# MCU_CPSW0_NUSS register map
Vendor: Texas Instruments
Peripheral module from a debugger description file (folder am65x).
Registers are 32-bit, read-write, reset 0x0 unless marked. A register's access mark holds for its fields unless they carry their own. Offsets are as the file gives them; lines under a group give offsets from that group; [hi:lo] are bit positions; {n}, {i} and the like mark numbered series; 'fields as' and 'values as' point back to an identical list; <NAME> marks a mode.

## MCU_CPSW0_NUSS (part 1 of 2)
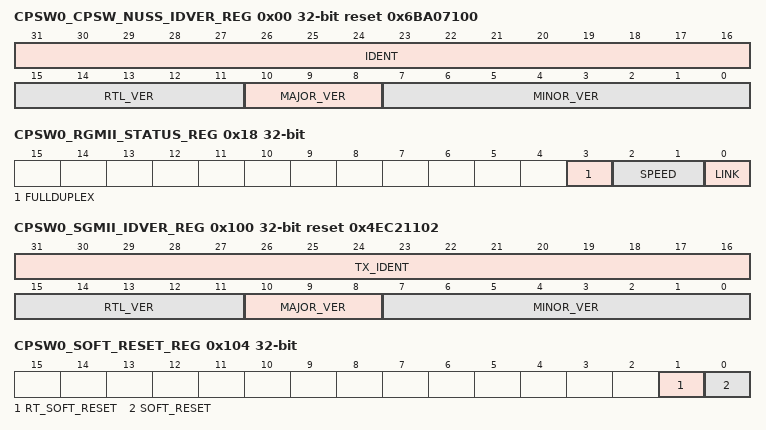
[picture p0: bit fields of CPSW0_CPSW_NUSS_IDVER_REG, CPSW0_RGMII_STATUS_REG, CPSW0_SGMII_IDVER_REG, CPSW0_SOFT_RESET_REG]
0x00 CPSW0_CPSW_NUSS_IDVER_REG ro reset 0x6BA07100 — ID Version Register
  [31:16] IDENT — Identification value
  [15:11] RTL_VER — RTL version value
  [10:8] MAJOR_VER — Major version value
  [7:0] MINOR_VER — Minor version value
0x04 CPSW0_SYNCE_COUNT_REG — SyncE Count Register
  [31:0] SYNCE_CNT — Sync E Count Value
0x08 CPSW0_SYNCE_MUX_REG — SyncE Mux Register
  [5:0] SYNCE_SEL — Sync E Select Value
0x10 CPSW0_SGMII_MODE_REG reset 0x1 — SyncE Mux Register
  [0] SYNCE_SEL — SGMII_MODE Input
0x18 CPSW0_RGMII_STATUS_REG ro — RGMII Status Register
  [3] FULLDUPLEX — Rgmii full dulex: 0=Half-duplex, 1=Full-duplex
  [2:1] SPEED — Rgmii speed: 00=10Mbps, 01=100Mbps, 10=1000Mbps, 11=reserved
  [0] LINK — Rgmii link indicator: 0=Link is down, 1=Link is up
0x1C CPSW0_SUBSSYSTEM_STATUS_REG ro — Subsystem Status Register
  [0] EEE_CLKSTOP_ACK — Energy Efficient Ethernet clockstop acknowledge from MCU_CPSW0_NUSS
0x100 CPSW0_SGMII_IDVER_REG ro reset 0x4EC21102 — SGMII Identification and Version Register.
  [31:16] TX_IDENT
  [15:11] RTL_VER — RTL version value
  [10:8] MAJOR_VER — Major version value
  [7:0] MINOR_VER — Minor version value
0x104 CPSW0_SOFT_RESET_REG — Software Reset Register.
  [1] RT_SOFT_RESET — Transmit and receive software reset
  [0] SOFT_RESET — Software reset
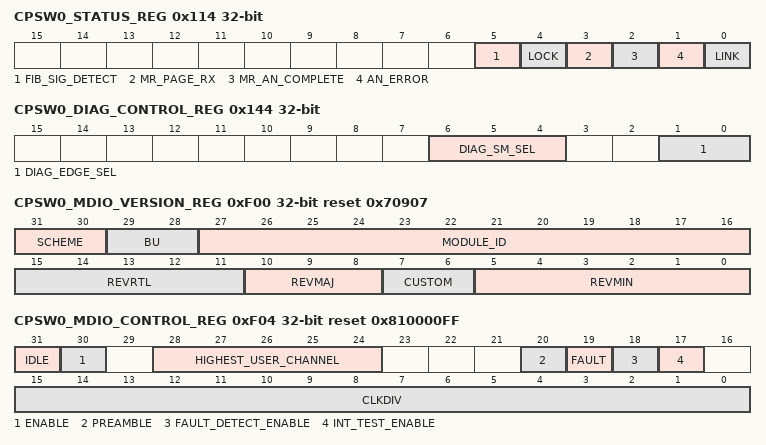
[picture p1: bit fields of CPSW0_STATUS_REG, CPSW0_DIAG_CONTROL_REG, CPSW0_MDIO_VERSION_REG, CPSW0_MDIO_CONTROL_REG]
0x114 CPSW0_STATUS_REG ro — Status Register.
  [5] FIB_SIG_DETECT — Fiber signal detect
  [4] LOCK
  [3] MR_PAGE_RX — Next page received
  [2] MR_AN_COMPLETE — Auto-negotiation complete
  [1] AN_ERROR — Auto-negotiation error
  [0] LINK — Link indicator
0x118 CPSW0_MR_ADV_ABILITY_REG — Advertised Ability Register.
  [15:0] MR_ADV_ABILITY — Advertised ability
0x11C CPSW0_MR_NP_TX_REG — Transmit Next Page Register.
  [15:0] MR_NP_TX — Next page transmit
0x120 CPSW0_MR_LP_ADV_ABILITY_REG ro — Link Partner Advertised Ability.
  [15:0] MR_LP_ADV_ABILITY — Link partner advertised ability
0x124 CPSW0_MR_LP_NP_RX_REG ro — Link Partner Receive Next Page Register.
  [15:0] MR_LP_NP_RX — Link Partner Next Page Received
0x130 CPSW0_TX_CFG_REG
  [31:0] TX_CFG — Transmit configuration register output
0x134 CPSW0_RX_CFG_REG
  [31:0] RX_CFG — Receive configuration register output
0x138 CPSW0_AUX_CFG_REG
  [31:0] AUX_CFG — Auxiliary configuration register output
0x140 CPSW0_DIAG_CLEAR_REG
  [0] DIAG_CLEAR — Diagnostics clear
0x144 CPSW0_DIAG_CONTROL_REG
  [6:4] DIAG_SM_SEL — Diagnostic select
  [1:0] DIAG_EDGE_SEL — Diagnostics hold signals edge select
0x148 CPSW0_DIAG_STATUS_REG ro
  [15:0] DIAG_STATUS — Diagnostics status
0xF00 CPSW0_MDIO_VERSION_REG ro reset 0x70907 — version_reg
  [31:30] SCHEME
  [29:28] BU
  [27:16] MODULE_ID
  [15:11] REVRTL — RTL version
  [10:8] REVMAJ — Major version
  [7:6] CUSTOM — Custom version
  [5:0] REVMIN — Minor version
0xF04 CPSW0_MDIO_CONTROL_REG access per field reset 0x810000FF
  [31] IDLE ro — MDIO state machine idle
  [30] ENABLE rw
  [28:24] HIGHEST_USER_CHANNEL ro
  [20] PREAMBLE rw — Preamble disable
  [19] FAULT rw — Fault indicator
  [18] FAULT_DETECT_ENABLE rw
  [17] INT_TEST_ENABLE rw — Interrupt test enable
  [15:0] CLKDIV rw — Clock divider
0xF08 CPSW0_ALIVE_REG — MDIO PHY Acknowledge Status Register
  [31:0] ALIVE — MDIO alive
0xF0C CPSW0_LINK_REG ro
  [31:0] LINK — MDIO link state
0xF10 CPSW0_LINK_INT_RAW_REG
  [1:0] LINKINTRAW — MDIO link change event raw value
0xF14 CPSW0_LINK_INT_MASKED_REG
  [1:0] LINKINTMASKED — MDIO link change interrupt masked value
0xF18 CPSW0_LINK_INT_MASK_SET_REG
  [0] LINKINTMASKSET — MDIO link interrupt mask set
0xF1C CPSW0_LINK_INT_MASK_CLEAR_REG
  [0] LINKINTMASKCLR — MDIO link interrupt mask clear
0xF20 CPSW0_USER_INT_RAW_REG
  [1:0] USERINTRAW — User interrupt raw
0xF24 CPSW0_USER_INT_MASKED_REG
  [1:0] USERINTMASKED — User interrupt masked
0xF28 CPSW0_USER_INT_MASK_SET_REG
  [1:0] USERINTMASKSET — MDIO user interrupt mask set
0xF2C CPSW0_USER_INT_MASK_CLEAR_REG
  [1:0] USERINTMASKCLR — MDIO user interrupt mask clear
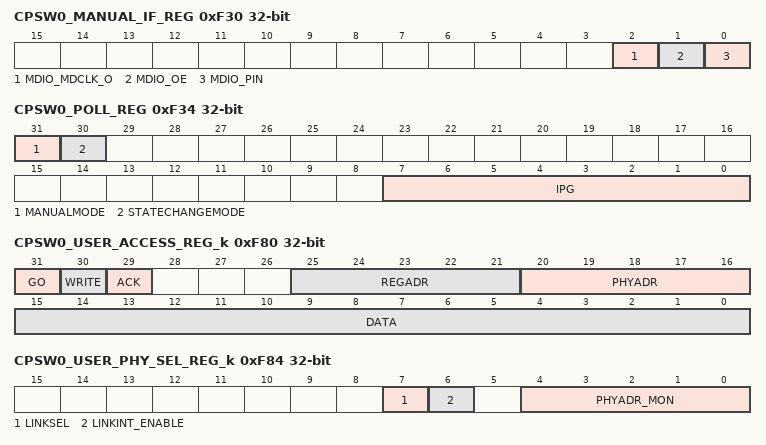
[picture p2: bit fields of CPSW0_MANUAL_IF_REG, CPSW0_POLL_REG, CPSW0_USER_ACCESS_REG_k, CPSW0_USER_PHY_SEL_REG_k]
0xF30 CPSW0_MANUAL_IF_REG
  [2] MDIO_MDCLK_O — MDIO Clock Output
  [1] MDIO_OE — MDIO Output Enable
  [0] MDIO_PIN
0xF34 CPSW0_POLL_REG
  [31] MANUALMODE — MDIO Manual Mode
  [30] STATECHANGEMODE — MDIO State Change Mode
  [7:0] IPG — MDIO IPG
0xF38 CPSW0_POLL_EN_REG reset 0xFFFFFFFF
  [31:0] POLL_EN — MDIO Poll Enable
0xF3C CPSW0_CLAUS45_REG — Clause 45 enable register.
  [31:0] CLAUSE45 — MDIO Clause 45
0xF40 CPSW0_USER_ADDR0_REG
  [15:0] USER_ADDR0 — MDIO USER Address 0
0xF44 CPSW0_USER_ADDR1_REG
  [15:0] USER_ADDR1 — MDIO USER Address 1
0xF80 CPSW0_USER_ACCESS_REG_k — user_access_reg Offset = F80h + (k * 8h); where k = 0h to 1h
  [31] GO
  [30] WRITE
  [29] ACK — Acknowledge
  [25:21] REGADR — Register address
  [20:16] PHYADR — PHY address
  [15:0] DATA — User data
0xF84 CPSW0_USER_PHY_SEL_REG_k — user_phy_sel_reg Offset = F84h + (k * 8h); where k = 0h to 1h
  [7] LINKSEL — Link status determination select
  [6] LINKINT_ENABLE — Link change interrupt enable
  [4:0] PHYADR_MON — PHY address whose link status is monitored
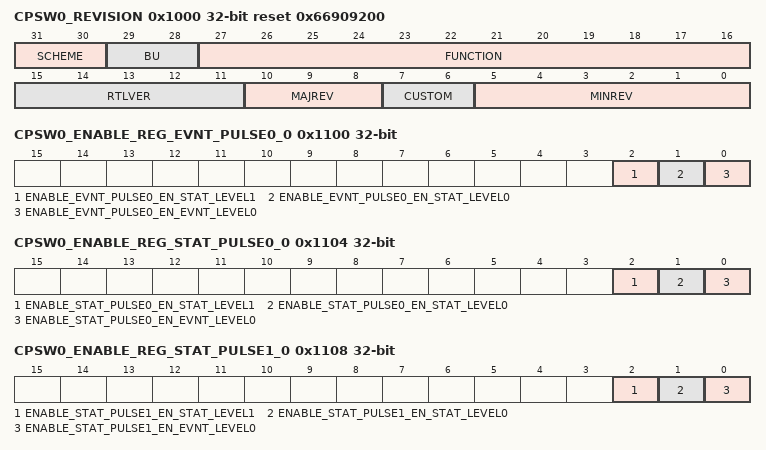
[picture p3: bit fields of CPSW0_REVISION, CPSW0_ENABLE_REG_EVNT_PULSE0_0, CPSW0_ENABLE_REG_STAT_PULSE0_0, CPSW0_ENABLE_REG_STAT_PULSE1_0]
0x1000 CPSW0_REVISION ro reset 0x66909200 — Revision Register
  [31:30] SCHEME
  [29:28] BU
  [27:16] FUNCTION — Module ID
  [15:11] RTLVER — RTL revisions
  [10:8] MAJREV — Major
  [7:6] CUSTOM
  [5:0] MINREV — Minor
0x1004 CPSW0_CONTROL size not given access not given reset not defined — Register
0x1010 CPSW0_EOI_REG — End of Interrupt Register
  [7:0] EOI_VECTOR — End of Interrupt Vector
0x1014 CPSW0_INTR_VECTOR_REG ro — Interrupt Vector Register
  [31:0] INTR_VECTOR
0x1100 CPSW0_ENABLE_REG_EVNT_PULSE0_0 access not given — Enable Register 0
  [2] ENABLE_EVNT_PULSE0_EN_STAT_LEVEL1 — Enable Set for evnt_pulse0_en_stat_level1 (access RW1S)
  [1] ENABLE_EVNT_PULSE0_EN_STAT_LEVEL0 — Enable Set for evnt_pulse0_en_stat_level0 (access RW1S)
  [0] ENABLE_EVNT_PULSE0_EN_EVNT_LEVEL0 — Enable Set for evnt_pulse0_en_evnt_level0 (access RW1S)
0x1104 CPSW0_ENABLE_REG_STAT_PULSE0_0 access not given — Enable Register 1
  [2] ENABLE_STAT_PULSE0_EN_STAT_LEVEL1 — Enable Set for stat_pulse0_en_stat_level1 (access RW1S)
  [1] ENABLE_STAT_PULSE0_EN_STAT_LEVEL0 — Enable Set for stat_pulse0_en_stat_level0 (access RW1S)
  [0] ENABLE_STAT_PULSE0_EN_EVNT_LEVEL0 — Enable Set for stat_pulse0_en_evnt_level0 (access RW1S)
0x1108 CPSW0_ENABLE_REG_STAT_PULSE1_0 access not given — Enable Register 2
  [2] ENABLE_STAT_PULSE1_EN_STAT_LEVEL1 — Enable Set for stat_pulse1_en_stat_level1 (access RW1S)
  [1] ENABLE_STAT_PULSE1_EN_STAT_LEVEL0 — Enable Set for stat_pulse1_en_stat_level0 (access RW1S)
  [0] ENABLE_STAT_PULSE1_EN_EVNT_LEVEL0 — Enable Set for stat_pulse1_en_evnt_level0 (access RW1S)
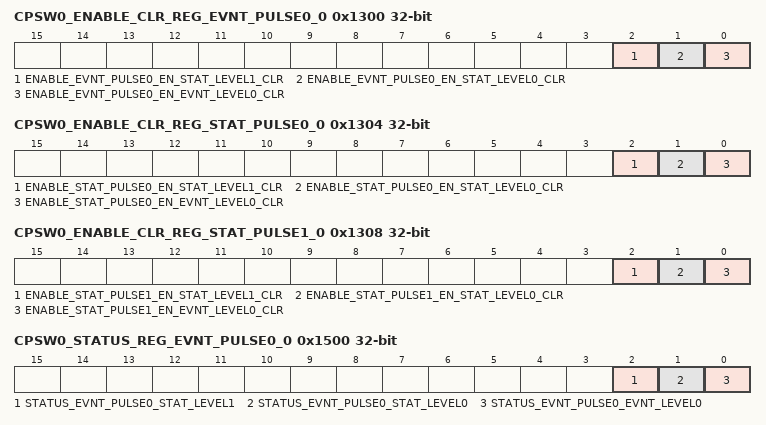
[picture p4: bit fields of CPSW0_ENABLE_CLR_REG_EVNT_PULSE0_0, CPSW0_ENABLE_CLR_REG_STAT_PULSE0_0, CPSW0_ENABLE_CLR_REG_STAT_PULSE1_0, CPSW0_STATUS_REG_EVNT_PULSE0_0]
0x1300 CPSW0_ENABLE_CLR_REG_EVNT_PULSE0_0 access not given — Enable Clear Register 0
  [2] ENABLE_EVNT_PULSE0_EN_STAT_LEVEL1_CLR — Enable Clear for evnt_pulse0_en_stat_level1 (access RW1C)
  [1] ENABLE_EVNT_PULSE0_EN_STAT_LEVEL0_CLR — Enable Clear for evnt_pulse0_en_stat_level0 (access RW1C)
  [0] ENABLE_EVNT_PULSE0_EN_EVNT_LEVEL0_CLR — Enable Clear for evnt_pulse0_en_evnt_level0 (access RW1C)
0x1304 CPSW0_ENABLE_CLR_REG_STAT_PULSE0_0 access not given — Enable Clear Register 1
  [2] ENABLE_STAT_PULSE0_EN_STAT_LEVEL1_CLR — Enable Clear for stat_pulse0_en_stat_level1 (access RW1C)
  [1] ENABLE_STAT_PULSE0_EN_STAT_LEVEL0_CLR — Enable Clear for stat_pulse0_en_stat_level0 (access RW1C)
  [0] ENABLE_STAT_PULSE0_EN_EVNT_LEVEL0_CLR — Enable Clear for stat_pulse0_en_evnt_level0 (access RW1C)
0x1308 CPSW0_ENABLE_CLR_REG_STAT_PULSE1_0 access not given — Enable Clear Register 2
  [2] ENABLE_STAT_PULSE1_EN_STAT_LEVEL1_CLR — Enable Clear for stat_pulse1_en_stat_level1 (access RW1C)
  [1] ENABLE_STAT_PULSE1_EN_STAT_LEVEL0_CLR — Enable Clear for stat_pulse1_en_stat_level0 (access RW1C)
  [0] ENABLE_STAT_PULSE1_EN_EVNT_LEVEL0_CLR — Enable Clear for stat_pulse1_en_evnt_level0 (access RW1C)
0x1500 CPSW0_STATUS_REG_EVNT_PULSE0_0 ro — Status Register 0
  [2] STATUS_EVNT_PULSE0_STAT_LEVEL1 — Status for evnt_pulse0_en_stat_level1
  [1] STATUS_EVNT_PULSE0_STAT_LEVEL0 — Status for evnt_pulse0_en_stat_level0
  [0] STATUS_EVNT_PULSE0_EVNT_LEVEL0 — Status for evnt_pulse0_en_evnt_level0
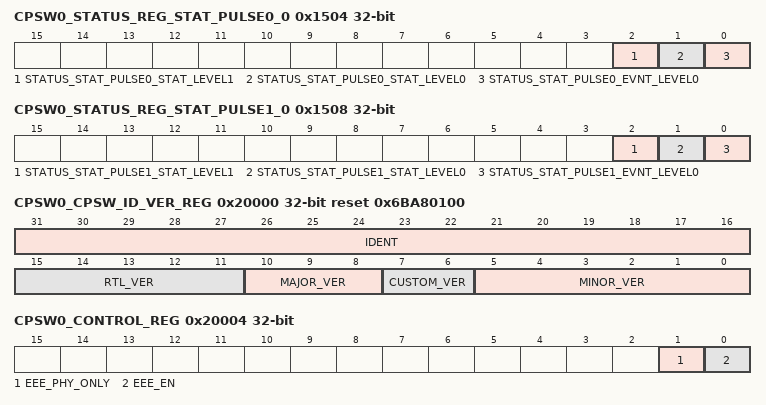
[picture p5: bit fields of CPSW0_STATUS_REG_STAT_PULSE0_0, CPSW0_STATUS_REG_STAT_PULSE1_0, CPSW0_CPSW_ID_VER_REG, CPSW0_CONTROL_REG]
0x1504 CPSW0_STATUS_REG_STAT_PULSE0_0 ro — Status Register 1
  [2] STATUS_STAT_PULSE0_STAT_LEVEL1 — Status for stat_pulse0_en_stat_level1
  [1] STATUS_STAT_PULSE0_STAT_LEVEL0 — Status for stat_pulse0_en_stat_level0
  [0] STATUS_STAT_PULSE0_EVNT_LEVEL0 — Status for stat_pulse0_en_evnt_level0
0x1508 CPSW0_STATUS_REG_STAT_PULSE1_0 ro — Status Register 2
  [2] STATUS_STAT_PULSE1_STAT_LEVEL1 — Status for stat_pulse1_en_stat_level1
  [1] STATUS_STAT_PULSE1_STAT_LEVEL0 — Status for stat_pulse1_en_stat_level0
  [0] STATUS_STAT_PULSE1_EVNT_LEVEL0 — Status for stat_pulse1_en_evnt_level0
0x1700 CPSW0_STATUS_CLR_REG_EVNT_PULSE0_0 size not given access not given reset not defined — Status Clear Register 0
0x1704 CPSW0_STATUS_CLR_REG_STAT_PULSE0_0 size not given access not given reset not defined — Status Clear Register 1
0x1708 CPSW0_STATUS_CLR_REG_STAT_PULSE1_0 size not given access not given reset not defined — Status Clear Register 2
0x1A80 CPSW0_INTR_VECTOR_REG_EVNT_PULSE0 ro — Interrupt Vector for evnt_pulse0
  [31:0] INTR_VECTOR_EVNT_PULSE0 — Interrupt Vector
0x1A84 CPSW0_INTR_VECTOR_REG_STAT_PULSE0 ro — Interrupt Vector for stat_pulse0
  [31:0] INTR_VECTOR_STAT_PULSE0 — Interrupt Vector
0x1A88 CPSW0_INTR_VECTOR_REG_STAT_PULSE1 ro — Interrupt Vector for stat_pulse1
  [31:0] INTR_VECTOR_STAT_PULSE1 — Interrupt Vector
0x20000 CPSW0_CPSW_ID_VER_REG ro reset 0x6BA80100 — MCU_CPSW0_NUSS ID Version
  [31:16] IDENT — Identification Value
  [15:11] RTL_VER — RTL Version Value
  [10:8] MAJOR_VER — Major Version Value
  [7:6] CUSTOM_VER — Custom Version Value
  [5:0] MINOR_VER — Minor Version Value
0x20004 CPSW0_CONTROL_REG — Control Register
  [1] EEE_PHY_ONLY — Energy Efficient Enable Phy Only Mode: 0=The low power indicate state includes gating off the CPPI_GCLK to the MCU_CPSW0_NUSS, 1=The low power indicate state does not gate the clock to the MCU_CPSW0_NUSS
  [0] EEE_EN — Energy Efficient Ethernet Enable: 0=EEE is disabled, 1=EEE is enabled
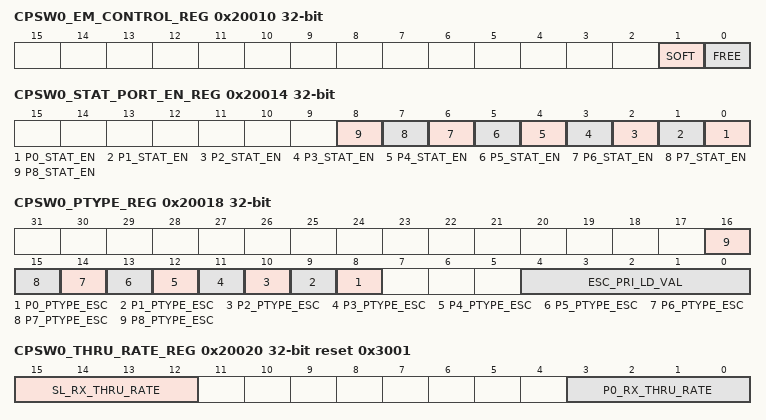
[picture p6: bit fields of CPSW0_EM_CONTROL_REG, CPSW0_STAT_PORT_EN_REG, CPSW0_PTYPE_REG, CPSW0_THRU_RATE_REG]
0x20010 CPSW0_EM_CONTROL_REG — MCU_CPSW0_NUSS Emulation Control
  [1] SOFT — Emulation Soft Bit
  [0] FREE — Emulation Free Bit
0x20014 CPSW0_STAT_PORT_EN_REG — MCU_CPSW0_NUSS Statistics Port Enable
  [n] P{n}_STAT_EN (n=0..8) — Port {n} Statistics Enable
0x20018 CPSW0_PTYPE_REG — MCU_CPSW0_NUSS Transmit Priority Type
  [n+8] P{n}_PTYPE_ESC (n=0..8) — Port {n} Priority Type Escalate
  [4:0] ESC_PRI_LD_VAL — Escalate Priority Load Value
0x2001C CPSW0_SOFT_IDLE_REG — MCU_CPSW0_NUSS Software Idle
  [0] SOFT_IDLE — Software Idle
0x20020 CPSW0_THRU_RATE_REG reset 0x3001 — MCU_CPSW0_NUSS Thru Rate
  [15:12] SL_RX_THRU_RATE — Switch FIFO receive through rate
  [3:0] P0_RX_THRU_RATE — CPPI FIFO receive through rate
0x20024 CPSW0_GAP_THRESH_REG reset 0xB — MCU_CPSW0_NUSS Transmit FIFO Short Gap Threshold
  [4:0] GAP_THRESH — Short Gap Threshold
0x20028 CPSW0_TX_START_WDS_REG reset 0x8 — MCU_CPSW0_NUSS Transmit FIFO Start Words
  [10:0] TX_START_WDS — FIFO Packet Transmit Start Words
0x2002C CPSW0_EEE_PRESCALE_REG — MCU_CPSW0_NUSS Energy Efficient Ethernet Prescale Value
  [11:0] EEE_PRESCALE — Energy Efficient Ethernet Pre-scale count load value
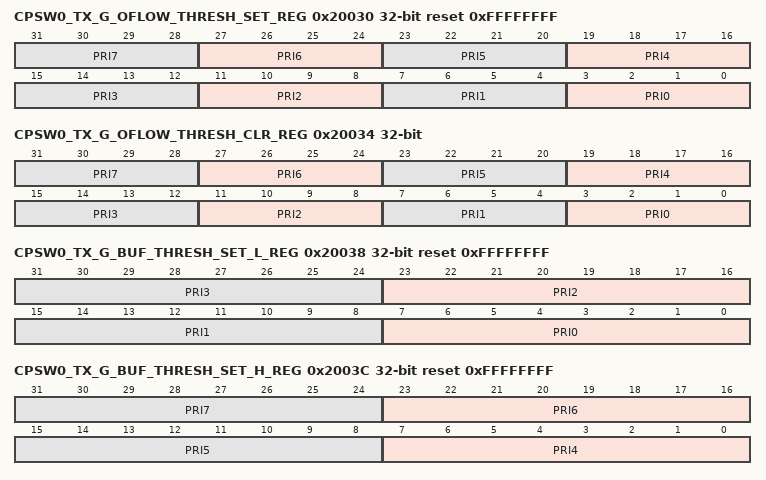
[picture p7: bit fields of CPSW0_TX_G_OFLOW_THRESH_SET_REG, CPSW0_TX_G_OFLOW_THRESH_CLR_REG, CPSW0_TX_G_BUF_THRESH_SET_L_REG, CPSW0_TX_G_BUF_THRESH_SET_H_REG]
0x20030 CPSW0_TX_G_OFLOW_THRESH_SET_REG reset 0xFFFFFFFF — MCU_CPSW0_NUSS PFC Tx Global Out Flow Threshold Set
  [4n+3:4n] PRI{n} (n=0..7) — Priority Based Flow Control Global Outflow Usage Threshold for Pri {n}
0x20034 CPSW0_TX_G_OFLOW_THRESH_CLR_REG — MCU_CPSW0_NUSS PFC Tx Global Out Flow Threshold Clear
  fields as CPSW0_TX_G_OFLOW_THRESH_SET_REG
0x20038 CPSW0_TX_G_BUF_THRESH_SET_L_REG reset 0xFFFFFFFF — MCU_CPSW0_NUSS PFC Global Tx Buffer Threshold Set Low
  [8n+7:8n] PRI{n} (n=0..3) — Priority Based Flow Control Global Buffer Usage Threshold for Priority {n}
0x2003C CPSW0_TX_G_BUF_THRESH_SET_H_REG reset 0xFFFFFFFF — MCU_CPSW0_NUSS PFC Global Tx Buffer Threshold Set High
  [8n-25:8n-32] PRI{n} (n=4..7) — Priority Based Flow Control Global Buffer Usage Threshold for Priority {n}
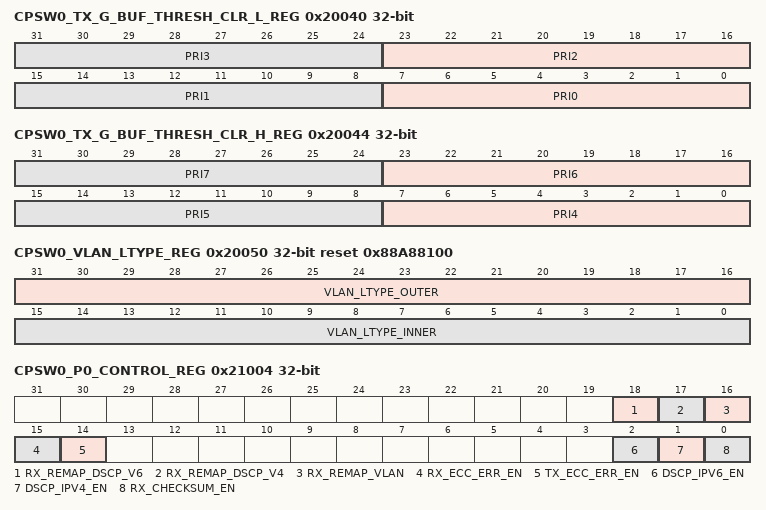
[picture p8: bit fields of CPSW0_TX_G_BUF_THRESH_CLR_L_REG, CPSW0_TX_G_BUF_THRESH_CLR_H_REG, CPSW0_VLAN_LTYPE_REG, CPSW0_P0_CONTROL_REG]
0x20040 CPSW0_TX_G_BUF_THRESH_CLR_L_REG — MCU_CPSW0_NUSS PFC Global Tx Buffer Threshold Clear Low
  fields as CPSW0_TX_G_BUF_THRESH_SET_L_REG
0x20044 CPSW0_TX_G_BUF_THRESH_CLR_H_REG — MCU_CPSW0_NUSS PFC Global Tx Buffer Threshold Clear High
  fields as CPSW0_TX_G_BUF_THRESH_SET_H_REG
0x20050 CPSW0_VLAN_LTYPE_REG reset 0x88A88100 — VLAN Length/type
  [31:16] VLAN_LTYPE_OUTER — Outer VLAN LType
  [15:0] VLAN_LTYPE_INNER — Inner VLAN LType
0x20054 CPSW0_EST_TS_DOMAIN_REG — Enhanced Scheduled Traffic Host Event Domain
  [7:0] EST_TS_DOMAIN
{0x20100+4i} CPSW0_TX_PRI{i}_MAXLEN_REG reset 0x7E8 (i=0..7) — Transmit Priority {i} Maximum Length
  [13:0] TX_PRI{i}_MAXLEN
0x21004 CPSW0_P0_CONTROL_REG — CPPI Port 0 Control
  [18] RX_REMAP_DSCP_V6 — Port 0 Remap DSCP_V6 Enable
  [17] RX_REMAP_DSCP_V4 — Port 0 Remap DSCP_V4 Enable
  [16] RX_REMAP_VLAN — Port 0 Remap VLAN Enable
  [15] RX_ECC_ERR_EN — Port 0 Receive ECC Error Enable
  [14] TX_ECC_ERR_EN — Port 0 Transmit ECC Error Enable
  [2] DSCP_IPV6_EN — Port 0 IPv6 DSCP enable
  [1] DSCP_IPV4_EN — Port 0 IPv4 DSCP enable
  [0] RX_CHECKSUM_EN — Port 0 Receive Checksum Enable
0x21008 CPSW0_P0_FLOW_ID_OFFSET_REG — CPPI Port 0 Flow ID Offset
  [13:0] VALUE — This value is added to the thread/Flow_ID in CPPI transmit PSI Info Word 0
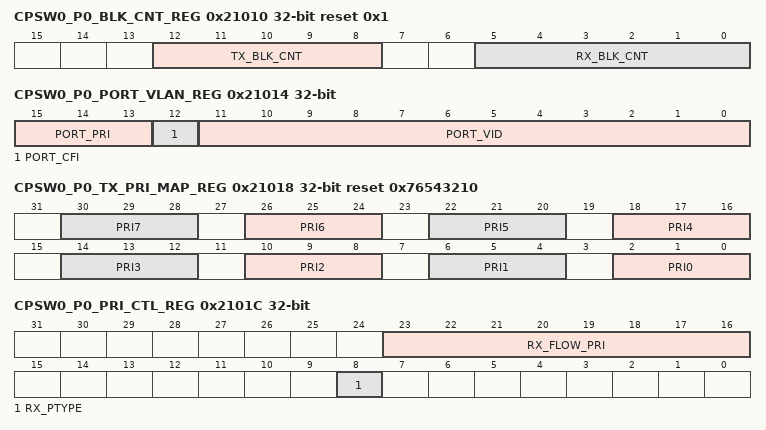
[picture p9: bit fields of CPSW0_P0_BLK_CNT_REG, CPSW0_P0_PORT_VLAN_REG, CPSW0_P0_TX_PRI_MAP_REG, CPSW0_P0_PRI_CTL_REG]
0x21010 CPSW0_P0_BLK_CNT_REG ro reset 0x1 — CPPI Port 0 FIFO Block Usage Count
  [12:8] TX_BLK_CNT — Port 0 Transmit Block Count Usage
  [5:0] RX_BLK_CNT — Port 0 Receive Block Count Usage
0x21014 CPSW0_P0_PORT_VLAN_REG — CPPI Port 0 VLAN
  [15:13] PORT_PRI — Port VLAN Priority
  [12] PORT_CFI — Port CFI bit
  [11:0] PORT_VID — Port VLAN ID
0x21018 CPSW0_P0_TX_PRI_MAP_REG reset 0x76543210 — CPPI Port 0 Tx Header Pri to Switch Pri Mapping
  [4n+2:4n] PRI{n} (n=0..7) — Priority {n}
0x2101C CPSW0_P0_PRI_CTL_REG — CPPI Port 0 Priority Control
  [23:16] RX_FLOW_PRI — Receive Priority Based Flow Control Enable (per priority)
  [8] RX_PTYPE — Receive Priority Type
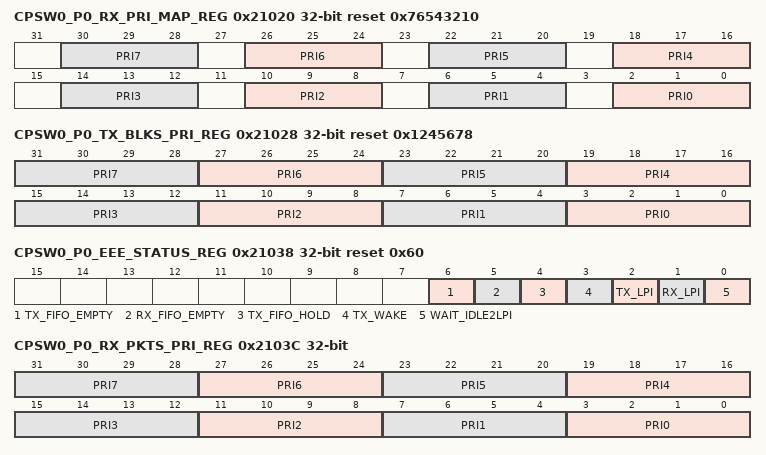
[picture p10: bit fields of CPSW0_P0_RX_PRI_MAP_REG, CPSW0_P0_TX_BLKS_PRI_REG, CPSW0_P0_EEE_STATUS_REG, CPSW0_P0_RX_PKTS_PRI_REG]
0x21020 CPSW0_P0_RX_PRI_MAP_REG reset 0x76543210 — CPPI Port 0 RX Pkt Pri to Header Pri Map
  [4n+2:4n] PRI{n} (n=0..7) — Priority {n}
0x21024 CPSW0_P0_RX_MAXLEN_REG reset 0x5EE — CPPI Port 0 Receive Frame Max Length
  [13:0] RX_MAXLEN — Rx Maximum Frame Length
0x21028 CPSW0_P0_TX_BLKS_PRI_REG reset 0x1245678 — CPPI Port 0 Transmit Block Sub Per Priority
  [4n+3:4n] PRI{n} (n=0..7) — Priority {n} Port Transmit Blocks
0x21030 CPSW0_P0_IDLE2LPI_REG — Port 0 EEE Idle to LPI counter
  [23:0] COUNT — Port 0 EEE Idle to LPI counter load value
0x21034 CPSW0_P0_LPI2WAKE_REG — Port 0 EEE LPI to wake counter
  [23:0] COUNT — Port 0 EEE LPI to wake counter load value
0x21038 CPSW0_P0_EEE_STATUS_REG ro reset 0x60 — Port 0 EEE status
  [6] TX_FIFO_EMPTY — CPPI port 0 transmit FIFO (switch egress) is empty - contains no packets
  [5] RX_FIFO_EMPTY — CPPI port 0 receive FIFO (switch ingress) is empty - contains no packets
  [4] TX_FIFO_HOLD — CPPI port 0 transmit FIFO hold - asserted in the LPI state and during the LPI2WAKE count time
  [3] TX_WAKE — CPPI port 0 transmit wakeup - asserted in the transmit LPI2WAKE count time
  [2] TX_LPI — CPPI port 0 transmit LPI state - asserted when the port 0 transmit is in the LPI state
  [1] RX_LPI — CPPI port 0 receive LPI state - asserted when the port 0 receive is in the LPI state
  [0] WAIT_IDLE2LPI — CPPI port 0 wait idle to LPI - asserted when port 0 is counting the IDLE2LPI time
0x2103C CPSW0_P0_RX_PKTS_PRI_REG — CPPI Port Receive Packets per priority
  [4n+3:4n] PRI{n} (n=0..7) — Priority {n} Port Port 0 Receive Packets
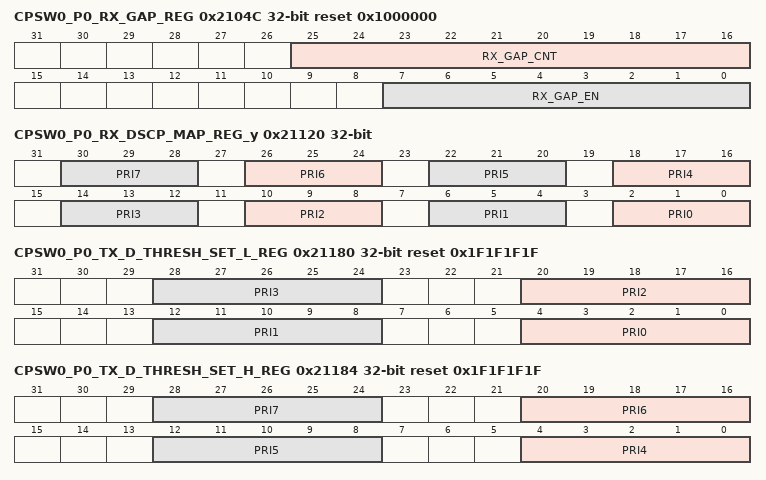
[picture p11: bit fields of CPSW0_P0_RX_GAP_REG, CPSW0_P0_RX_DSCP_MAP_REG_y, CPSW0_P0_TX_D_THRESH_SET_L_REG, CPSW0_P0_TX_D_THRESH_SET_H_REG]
0x2104C CPSW0_P0_RX_GAP_REG reset 0x1000000 — Port 0 Receive Gap Register
  [25:16] RX_GAP_CNT — Port 0 Receive Gap Count
  [7:0] RX_GAP_EN — Port 0 Receive Gap Enable
0x21050 CPSW0_P0_FIFO_STATUS_REG ro — Port 0 FIFO Status
  [7:0] TX_PRI_ACTIVE
0x21120 CPSW0_P0_RX_DSCP_MAP_REG_y — CPPI Port 0 Receive IPV4/IPV6 DSCP Map N Offset = 00021120h + (y * 4h); where y = 0h to 7h
  [4n+2:4n] PRI{n} (n=0..7) — A DSCP IPV4/V6 packet TOS of N*8+{n} is mapped to this received priority
0x21140 CPSW0_P0_PRI_CIR_REG_y — CPPI Port 0 Rx Priority P Committed Information Rate Offset = 00021140h + (y * 4h); where y = 0h to 7h
  [27:0] PRI_CIR — Priority N CIR
0x21160 CPSW0_P0_PRI_EIR_REG_y — CPPI Port 0 Rx Priority P Excess Information Rate Offset = 00021160h + (y * 4h); where y = 0h to 7h
  [27:0] PRI_EIR — Priority N EIR
0x21180 CPSW0_P0_TX_D_THRESH_SET_L_REG reset 0x1F1F1F1F — CPPI Port 0 Tx PFC Destination Threshold Set Low
  [8n+4:8n] PRI{n} (n=0..3) — Port Priority Based Flow Control Threshold Set Value for Priority {n}
0x21184 CPSW0_P0_TX_D_THRESH_SET_H_REG reset 0x1F1F1F1F — CPPI Port 0 Tx PFC Destination Threshold Set High
  [8n-28:8n-32] PRI{n} (n=4..7) — Port Priority Based Flow Control Threshold Set Value for Priority {n}
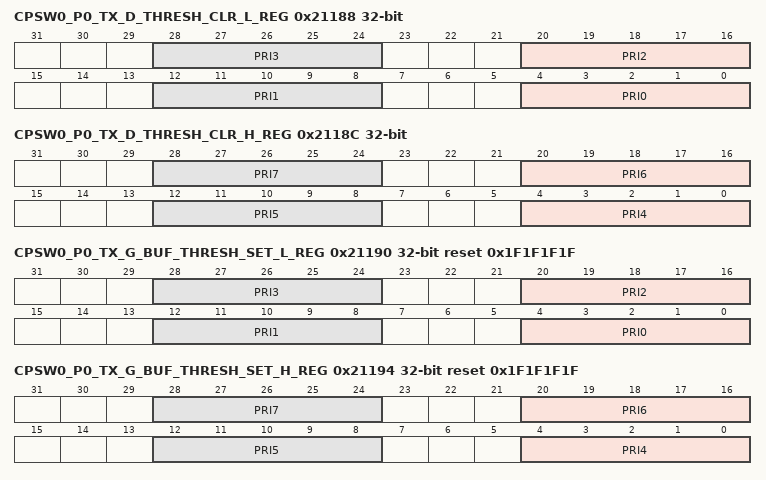
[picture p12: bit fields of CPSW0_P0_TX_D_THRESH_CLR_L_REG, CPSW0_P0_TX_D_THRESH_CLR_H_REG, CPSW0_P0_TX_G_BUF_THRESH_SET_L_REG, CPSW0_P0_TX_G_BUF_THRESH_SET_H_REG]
0x21188 CPSW0_P0_TX_D_THRESH_CLR_L_REG — CPPI Port 0 Tx PFC Destination Threshold Clr Low
  [8n+4:8n] PRI{n} (n=0..3) — Port Priority Based Flow Control Threshold Clear Value for Priority {n}
0x2118C CPSW0_P0_TX_D_THRESH_CLR_H_REG — CPPI Port 0 Tx PFC Destination Threshold Clr High
  [8n-28:8n-32] PRI{n} (n=4..7) — Port Priority Based Flow Control Threshold Clear Value for Priority {n}
0x21190 CPSW0_P0_TX_G_BUF_THRESH_SET_L_REG reset 0x1F1F1F1F — CPPI Port 0 Tx PFC Global Buffer Threshold Set Low
  fields as CPSW0_P0_TX_D_THRESH_SET_L_REG
0x21194 CPSW0_P0_TX_G_BUF_THRESH_SET_H_REG reset 0x1F1F1F1F — CPPI Port 0 Tx PFC Global Buffer Threshold Set High
  fields as CPSW0_P0_TX_D_THRESH_SET_H_REG
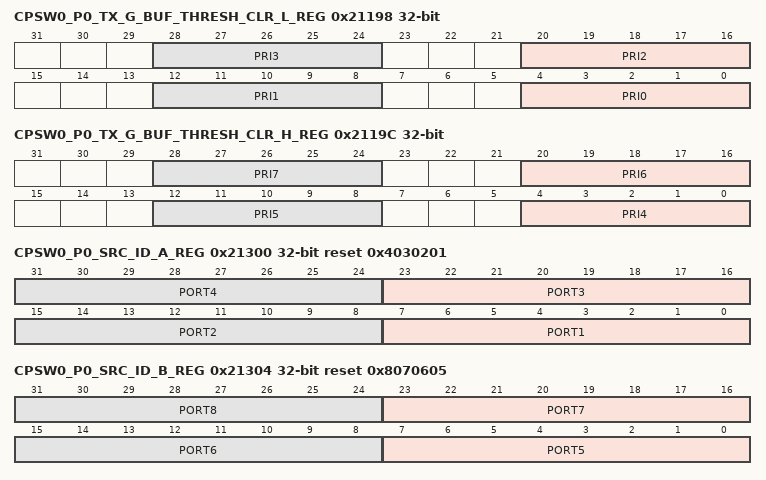
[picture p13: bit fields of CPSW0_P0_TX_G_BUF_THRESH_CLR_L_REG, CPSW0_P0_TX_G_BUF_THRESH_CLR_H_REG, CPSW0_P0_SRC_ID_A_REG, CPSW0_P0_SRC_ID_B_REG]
0x21198 CPSW0_P0_TX_G_BUF_THRESH_CLR_L_REG — CPPI Port 0 Tx PFC Global Buffer Threshold Clr Low
  fields as CPSW0_P0_TX_D_THRESH_CLR_L_REG
0x2119C CPSW0_P0_TX_G_BUF_THRESH_CLR_H_REG — CPPI Port 0 Tx PFC Global Buffer Threshold Clr High
  fields as CPSW0_P0_TX_D_THRESH_CLR_H_REG
0x21300 CPSW0_P0_SRC_ID_A_REG reset 0x4030201 — CPPI Port 0 CPPI Source ID A
  [8n-1:8n-8] PORT{n} (n=1..4) — Port {n} CPPI Info Word0 Source ID Value
0x21304 CPSW0_P0_SRC_ID_B_REG reset 0x8070605 — CPPI Port 0 CPPI Source ID B
  [8n-33:8n-40] PORT{n} (n=5..8) — Port {n} CPPI Info Word0 Source ID Value
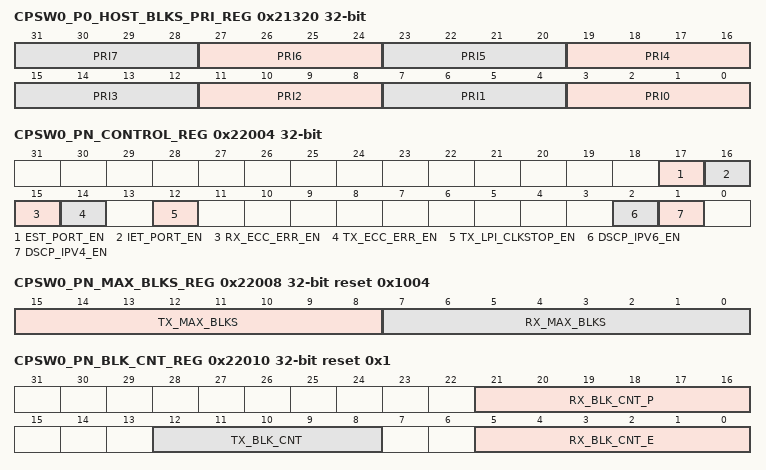
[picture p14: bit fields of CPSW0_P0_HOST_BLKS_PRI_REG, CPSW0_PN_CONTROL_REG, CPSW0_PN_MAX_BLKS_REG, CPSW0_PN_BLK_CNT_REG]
0x21320 CPSW0_P0_HOST_BLKS_PRI_REG — CPPI Port 0 Host Blocks Priority
  [4n+3:4n] PRI{n} (n=0..7) — Priority {n} Host Blocks
0x22000 CPSW0_PN_RESERVED_REG ro — Reserved
0x22004 CPSW0_PN_CONTROL_REG — Enet Port N Control
  [17] EST_PORT_EN — EST Port Enable
  [16] IET_PORT_EN — IET Port Enable
  [15] RX_ECC_ERR_EN — Port 0 Receive ECC Error Enable
  [14] TX_ECC_ERR_EN — Port 0 Transmit ECC Error Enable
  [12] TX_LPI_CLKSTOP_EN — Transmit LPI clockstop enable
  [2] DSCP_IPV6_EN — IPv6 DSCP enable
  [1] DSCP_IPV4_EN — IPv4 DSCP enable
0x22008 CPSW0_PN_MAX_BLKS_REG reset 0x1004 — Enet Port N FIFO Max Blocks
  [15:8] TX_MAX_BLKS — Transmit FIFO maximum blocks
  [7:0] RX_MAX_BLKS — Receive FIFO maximum blocks
0x22010 CPSW0_PN_BLK_CNT_REG ro reset 0x1 — Enet Port N FIFO Block Usage Count
  [21:16] RX_BLK_CNT_P — Receive Prempt Queue Block Count Usage
  [12:8] TX_BLK_CNT — Transmit Block Count Usage
  [5:0] RX_BLK_CNT_E — Receive Block Count Usage
0x22014 CPSW0_PN_PORT_VLAN_REG — Enet Port N VLAN
  fields as CPSW0_P0_PORT_VLAN_REG
0x22018 CPSW0_PN_TX_PRI_MAP_REG reset 0x76543210 — Enet Port N Tx Header Pri to Switch Pri Mapping
  [4n+2:4n] PRI{n} (n=0..7) — Priority {n}
0x2201C CPSW0_PN_PRI_CTL_REG reset 0x9000 — Enet Port N Priority Control
  [31:24] TX_FLOW_PRI — Transmit Priority Based Flow Control Enable (per priority)
  [23:16] RX_FLOW_PRI — Receive Priority Based Flow Control Enable (per priority)
  [15:12] TX_HOST_BLKS_REM — Transmit FIFO Blocks that must be free before a non rate-limited CPPI Port 0 receive thread can begin sending a packet
0x22020 CPSW0_PN_RX_PRI_MAP_REG reset 0x76543210 — Enet Port N RX Pkt Pri to Header Pri Map
  [4n+2:4n] PRI{n} (n=0..7) — Priority {n}
0x22024 CPSW0_PN_RX_MAXLEN_REG reset 0x5EE — Enet Port N Receive Frame Max Length
  [13:0] RX_MAXLEN — Rx Maximum Frame Length
0x22028 CPSW0_PN_TX_BLKS_PRI_REG reset 0x1245678 — Enet Port N Transmit Block Sub Per Priority
  [4n+3:4n] PRI{n} (n=0..7) — Priority {n} Port Transmit Blocks
0x2202C CPSW0_PN_RX_FLOW_THRESH_REG reset 0x40 — Enet MAC Receive Flow Threshold in Receive Buffer Words
  [8:0] COUNT — Receive Flow Threshold in Words
0x22030 CPSW0_PN_IDLE2LPI_REG — Enet Port N EEE Idle to LPI counter
  [23:0] COUNT — EEE Idle to LPI counter load value
0x22034 CPSW0_PN_LPI2WAKE_REG — Enet Port N EEE LPI to wake counter
  [23:0] COUNT — EEE LPI to wake counter load value
0x22038 CPSW0_PN_EEE_STATUS_REG ro reset 0x62 — Enet Port N EEE status
  [6] TX_FIFO_EMPTY — Transmit FIFO (switch egress) is empty - contains no packets
  [5] RX_FIFO_EMPTY — Receive FIFO (switch ingress) is empty - contains no packets
  [4] TX_FIFO_HOLD — Transmit FIFO hold - asserted in the LPI state and during the LPI2WAKE count time
  [3] TX_WAKE — Transmit wakeup - asserted in the transmit LPI2WAKE count time
  [2] TX_LPI — Transmit LPI state - asserted when the port 0 transmit is in the LPI state
  [1] RX_LPI — Receive LPI state - asserted when the port 0 receive is in the LPI state
  [0] WAIT_IDLE2LPI — CPPI port 0 wait idle to LPI - asserted when port 0 is counting the IDLE2LPI time
0x22050 CPSW0_PN_FIFO_STATUS_REG ro reset 0xFF00 — Enet Port N FIFO STATUS
  [18] EST_BUFACT — Transmit FIFO EST Buffer Active
  [17] EST_ADD_ERR — Transmit FIFO EST Address Error
  [16] EST_CNT_ERR — Transmit FIFO EST Count Error
  [15:8] TX_E_MAC_ALLOW — Transmit FIFO Express Queue Priority Allow
  [7:0] TX_PRI_ACTIVE — Transmit FIFO Priority Active
0x22060 CPSW0_PN_EST_CONTROL_REG — Enet Port N EST
  [25:16] EST_FILL_MARGIN — Transmit FIFO EST Fill Margin
  [8] EST_FILL_EN — Transmit FIFO EST Fill Enable
  [7:5] EST_TS_PRI — Transmit FIFO EST TimeStamp Priority
  [4] EST_TS_ONEPRI — Transmit FIFO EST TimeStamp One Priority
  [3] EST_TS_FIRST — Transmit FIFO EST TimeStamp First Express Packet
  [2] EST_TS_EN — Transmit FIFO EST TimeStamp Enable
  [1] EST_BUFSEL — Transmit FIFO EST Buffer Select
  [0] EST_ONEBUF — Transmit FIFO EST One Buffer
0x22120 CPSW0_PN_RX_DSCP_MAP_REG_y — Enet Port N Receive IPV4/IPV6 DSCP Map M Offset = 00022120h + (y * 4h); where y = 0h to 7h
  fields as CPSW0_P0_RX_DSCP_MAP_REG_y
0x22140 CPSW0_PN_PRI_CIR_REG_y — Enet Port N Rx Priority P Committed Information Rate Value Offset = 00022140h + (y * 4h); where y = 0h to 7h
  [27:0] PRI_CIR — Priority N committed information rate
0x22160 CPSW0_PN_PRI_EIR_REG_y — Enet Port N Rx Priority P Excess Informatoin Rate Value Offset = 00022160h + (y * 4h); where y = 0h to 7h
  [27:0] PRI_EIR — Priority N Excess Information Rate count
0x22180 CPSW0_PN_TX_D_THRESH_SET_L_REG reset 0x1F1F1F1F — Enet Port N Tx PFC Destination Threshold Set Low
  fields as CPSW0_P0_TX_D_THRESH_SET_L_REG
0x22184 CPSW0_PN_TX_D_THRESH_SET_H_REG reset 0x1F1F1F1F — Enet Port N Tx PFC Destination Threshold Set High
  fields as CPSW0_P0_TX_D_THRESH_SET_H_REG
0x22188 CPSW0_PN_TX_D_THRESH_CLR_L_REG — Enet Port N Tx PFC Destination Threshold Clr Low
  fields as CPSW0_P0_TX_D_THRESH_CLR_L_REG
0x2218C CPSW0_PN_TX_D_THRESH_CLR_H_REG — Enet Port N Tx PFC Destination Threshold Clr High
  fields as CPSW0_P0_TX_D_THRESH_CLR_H_REG
0x22190 CPSW0_PN_TX_G_BUF_THRESH_SET_L_REG reset 0x1F1F1F1F — Enet Port N Tx PFC Global Buffer Threshold Set Low
  fields as CPSW0_P0_TX_D_THRESH_SET_L_REG
0x22194 CPSW0_PN_TX_G_BUF_THRESH_SET_H_REG reset 0x1F1F1F1F — Enet Port N Tx PFC Global Buffer Threshold Set High
  fields as CPSW0_P0_TX_D_THRESH_SET_H_REG
0x22198 CPSW0_PN_TX_G_BUF_THRESH_CLR_L_REG — Enet Port N Tx PFC Global Buffer Threshold Clr Low
  fields as CPSW0_P0_TX_D_THRESH_CLR_L_REG
0x2219C CPSW0_PN_TX_G_BUF_THRESH_CLR_H_REG — Enet Port N Tx PFC Global Buffer Threshold Clr High
  fields as CPSW0_P0_TX_D_THRESH_CLR_H_REG
0x22300 CPSW0_PN_TX_D_OFLOW_ADDVAL_L_REG — Enet Port N Tx Destination Out Flow Add Values Low
  [8n+4:8n] PRI{n} (n=0..3) — Port PFC Destination Based Out Flow Add Value for Priority {n}
0x22304 CPSW0_PN_TX_D_OFLOW_ADDVAL_H_REG — Enet Port N Tx Destination Out Flow Add Values High
  [8n-28:8n-32] PRI{n} (n=4..7) — Port PFC Destination Based Out Flow Add Value for Priority {n}
0x22308 CPSW0_PN_SA_L_REG — Enet Port N Tx Pause Frame Source Address Low
  [15:8] MACSRCADDR_7_0 — Source Address Lower 8 bits
  [7:0] MACSRCADDR_15_8 — Source Address bits 15:8
0x2230C CPSW0_PN_SA_H_REG — Enet Port N Tx Pause Frame Source Address High
  [31:24] MACSRCADDR_23_16 — Source Address bits 23:16
  [23:16] MACSRCADDR_31_24 — Source Address bits 31:24
  [15:8] MACSRCADDR_39_32 — Source Address bits 39:32
  [7:0] MACSRCADDR_47_40 — Source Address bits 47:40
0x22310 CPSW0_PN_TS_CTL_REG — Enet Port N Time Sync Control
  [31:16] TS_MSG_TYPE_EN — Time Sync Message Type Enable
  [11] TS_TX_HOST_TS_EN — Time Sync Transmit Host Time Stamp Enable
  [10] TS_TX_ANNEX_E_EN — Time Synce Transmit Annex E Enable
  [9] TS_RX_ANNEX_E_EN — Time Synce Receive Annex E Enable
  [8] TS_LTYPE2_EN — Time Sync LTYPE 2 enable transmit and receive
  [7] TS_TX_ANNEX_D_EN — Time Synce Transmit Annex D Enable
  [6] TS_TX_VLAN_LTYPE2_EN — Time Sync Transmit VLAN LTYPE 2 enable
  [5] TS_TX_VLAN_LTYPE1_EN — Time Sync Transmit VLAN LTYPE 1 enable
  [4] TS_TX_ANNEX_F_EN — Time Synce Transmit Annex F Enable
  [3] TS_RX_ANNEX_D_EN — Time Synce Receive Annex D Enable
  [2] TS_RX_VLAN_LTYPE2_EN — Time Sync Receive VLAN LTYPE 2 enable
  [1] TS_RX_VLAN_LTYPE1_EN — Time Sync Receive VLAN LTYPE 1 enable
  [0] TS_RX_ANNEX_F_EN — Time Synce Receive Annex F Enable
0x22314 CPSW0_PN_TS_SEQ_LTYPE_REG reset 0x1E0000 — Enet Port N Time Sync LTYPE (and SEQ_ID_OFFSET)
  [21:16] TS_SEQ_ID_OFFSET — Time Sync Sequence ID Offset
  [15:0] TS_LTYPE1 — Time Sync LTYPE1
0x22318 CPSW0_PN_TS_VLAN_LTYPE_REG — Enet Port N Time Sync VLAN2 and VLAN2
  [31:16] TS_VLAN_LTYPE2 — Time Sync VLAN LTYPE2
  [15:0] TS_VLAN_LTYPE1 — Time Sync VLAN LTYPE1
0x2231C CPSW0_PN_TS_CTL_LTYPE2_REG — Enet Port N Time Sync Control and LTYPE 2
  [24] TS_UNI_EN — Time Sync Unicast Enable
  [23] TS_TTL_NONZERO — Time Sync Time to Live Non-zero Enable
  [22] TS_320 — Time Sync Destination IP Address 320 Enable
  [21] TS_319 — Time Sync Destination IP Address 319 Enable
  [n-112] TS_{n} (n=129..132) — Time Sync Destination IP Address {n} Enable
  [16] TS_107 — Time Sync Destination IP Address 107 Enable
  [15:0] TS_LTYPE2 — Time Sync LTYPE2
